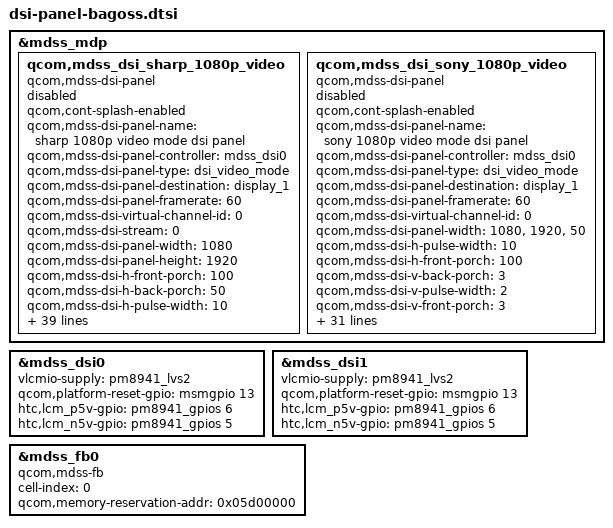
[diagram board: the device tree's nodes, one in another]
&mdss_mdp {
	qcom,mdss_dsi_sharp_1080p_video {
		compatible = "qcom,mdss-dsi-panel";
		status = "disable";
		qcom,cont-splash-enabled;
		qcom,mdss-dsi-panel-name = "sharp 1080p video mode dsi panel";
		qcom,mdss-dsi-panel-controller = <&mdss_dsi0>;
		qcom,mdss-dsi-panel-type = "dsi_video_mode";
		qcom,mdss-dsi-panel-destination = "display_1";
		qcom,mdss-dsi-panel-framerate = <60>;
		qcom,mdss-dsi-virtual-channel-id = <0>;
		qcom,mdss-dsi-stream = <0>;
		qcom,mdss-dsi-panel-width = <1080>;
		qcom,mdss-dsi-panel-height = <1920>;
		qcom,mdss-dsi-h-front-porch = <100>;
		qcom,mdss-dsi-h-back-porch = <50>;
		qcom,mdss-dsi-h-pulse-width = <10>;
		qcom,mdss-dsi-h-sync-skew = <0>;
		qcom,mdss-dsi-v-back-porch = <4>;
		qcom,mdss-dsi-v-front-porch = <4>;
		qcom,mdss-dsi-v-pulse-width = <2>;
		qcom,mdss-dsi-h-left-border = <0>;
		qcom,mdss-dsi-h-right-border = <0>;
		qcom,mdss-dsi-v-top-border = <0>;
		qcom,mdss-dsi-v-bottom-border = <0>;
		qcom,mdss-dsi-bpp = <24>;
		qcom,mdss-dsi-color-order = "rgb_swap_rgb";
		qcom,mdss-dsi-underflow-color = <0xff>;
		qcom,mdss-dsi-border-color = <0>;
		qcom,mdss-dsi-on-command = [29 01 00 00 00 00 02 b0 04 /* interface_setting_0 */
			15 01 00 00 00 00 02 00 00 /* nop */
			15 01 00 00 00 00 02 00 00 /* nop */
			29 01 00 00 00 00 02 d6 01 /* Manufacture_Command_setting */
			29 01 00 00 00 00 02 b3 14 /* Config to Video Mode */
			/* Color_enhancement */
			29 01 00 00 00 00 21 ca 01 02 a4 a4 b8 b4 b0
				a4 3f 28 05 b9 90 70 01
				ff 05 f8 0c 0c 0c 0c 13
				13 f0 20 10 10 10 10 10
				10
			/* BackLight_Control_6 */
			29 01 00 00 00 00 08 ce 00 07 00 c1 24 b2 02
			15 01 00 00 00 00 02 53 24 /* write_control_display */
			15 01 00 00 00 00 02 55 01 /* CABC */
			15 01 00 00 00 00 02 35 00 /* TE_OUT */
			05 01 00 00 78 00 02 11 00 ];
		qcom,mdss-dsi-off-command = [29 01 00 00 14 00 02 28 00 /* display_off */
			29 01 00 00 32 00 02 10 00];
		qcom,mdss-dsi-on-command-state = "dsi_lp_mode"
		qcom,mdss-dsi-off-command-state = "dsi_hs_mode"

		qcom,mdss-dsi-h-sync-pulse = <0>;
		qcom,mdss-dsi-traffic-mode = "non_burst_sync_event";
		qcom,mdss-dsi-bllp-power-mode;
		qcom,mdss-dsi-bllp-eof-power-mode
		qcom,mdss-dsi-lane-map = "lane_map_0123";
		qcom,mdss-dsi-lane-0-state;
		qcom,mdss-dsi-lane-1-state;
		qcom,mdss-dsi-lane-2-state;
		qcom,mdss-dsi-lane-3-state;
		qcom,mdss-dsi-panel-timings = [c8 40 33 00 57 51 35 42 55 03 04 00];
		qcom,mdss-dsi-t-clk-post = <0x02>;
		qcom,mdss-dsi-t-clk-pre = <0x2a>;
		qcom,mdss-dsi-bl-min-level = <1>;
		qcom,mdss-dsi-bl-max-level = <4095>;
		qcom,mdss-dsi-dma-trigger = "trigger_sw";
		qcom,mdss-dsi-mdp-trigger = "none";
		qcom,mdss-dsi-bl-pmic-control-type = "bl_ctrl_wled";

		qcom,display-on-cmds = [39 01 00 00 00 00 02 29 00];
		qcom,mdss-pan-physical-width-dimension = <61>;
		qcom,mdss-pan-physical-height-dimension = <109>;
	};

	qcom,mdss_dsi_sony_1080p_video {
        compatible = "qcom,mdss-dsi-panel";
		status = "disable";
		qcom,cont-splash-enabled;
		qcom,mdss-dsi-panel-name = "sony 1080p video mode dsi panel";
		qcom,mdss-dsi-panel-controller = <&mdss_dsi0>;

		qcom,mdss-dsi-panel-type = "dsi_video_mode";
		qcom,mdss-dsi-panel-destination = "display_1";
		qcom,mdss-dsi-panel-framerate = <60>;
		qcom,mdss-dsi-virtual-channel-id = <0>;
		qcom,mdss-dsi-panel-width = <1080>
		qcom,mdss-dsi-panel-height = <1920>
		qcom,mdss-dsi-h-back-porch = <50>;
		qcom,mdss-dsi-h-pulse-width = <10>;
		qcom,mdss-dsi-h-front-porch = <100>;
		qcom,mdss-dsi-v-back-porch = <3>;
		qcom,mdss-dsi-v-pulse-width = <2>;
		qcom,mdss-dsi-v-front-porch = <3>;
		qcom,mdss-dsi-underflow-color = <0xff>;
		qcom,mdss-dsi-h-sync-pulse = <0>
		qcom,mdss-dsi-bllp-power-mode;
		qcom,mdss-dsi-bllp-eof-power-mode
		qcom,mdss-dsi-bpp = <24>;
		qcom,mdss-dsi-traffic-mode = "non_burst_sync_event";
		qcom,mdss-dsi-color-order = "rgb_swap_rgb";
		qcom,mdss-dsi-on-command = [29 01 00 00 00 00 02 b0 04	/* interface_setting_0 */
			15 01 00 00 00 00 02 00 00 /* nop */
			15 01 00 00 00 00 02 00 00 /* nop */
			/* hsync output */
			29 01 00 00 00 00 04 c3 01 00 10
			/* Color_enhancement */
			29 01 00 00 0a 00 21 ca 01 02 a4 a4 b8 b4 b0
				a4 3f 28 05 b9 90 70 01
				ff 05 f8 0c 0c 0c 0c 13
				13 f0 20 10 10 10 10 10
				10
			/* BackLight_Control_6 */
			29 01 00 00 00 00 08 ce 00 07 00 c1 24 b2 02
			29 01 00 00 00 00 02 d6 01 /* Manufacture Command setting */
			29 01 00 00 00 00 02 b0 03 /* protect on */
			15 01 00 00 00 00 02 00 00 /* nop */
			15 01 00 00 00 00 02 00 00 /* nop */
			15 01 00 00 00 00 02 55 01 /* CABC */
			15 01 00 00 00 00 02 53 24 /* write_control_display */
			15 01 00 00 00 00 02 35 00 /* TE_OUT */
			05 01 00 00 78 00 02 11 00 ];
		qcom,mdss-dsi-off-command = [29 01 00 00 14 00 02 28 00 /* display_off */
		                       29 01 00 00 32 00 02 10 00 /* enter sleep 1 */
		                       29 01 00 00 00 00 02 b0 04 /* interface setting 0 */
		                       15 01 00 00 00 00 02 00 00 /* nop */
		                       15 01 00 00 00 00 02 00 00 /* nop */
		                       29 01 00 00 00 00 02 b0 01 /* interface setting 0 */];
		qcom,mdss-dsi-on-command-state = "dsi_lp_mode"
		qcom,mdss-dsi-off-command-state = "dsi_hs_mode"
		qcom,mdss-dsi-lane-0-state;
		qcom,mdss-dsi-lane-1-state;
		qcom,mdss-dsi-lane-2-state;
		qcom,mdss-dsi-lane-3-state;
		qcom,mdss-dsi-lane-map = "lane_map_0123";
		qcom,mdss-dsi-t-clk-post = <0x02>;
		qcom,mdss-dsi-t-clk-pre = <0x2a>;
		qcom,mdss-dsi-stream = <0>;
		qcom,mdss-dsi-mdp-trigger = "none";
		qcom,mdss-dsi-dma-trigger = "trigger_sw";
		qcom,mdss-dsi-panel-timings = [cb 40 33 00 57 51 35 42 52 03 04 00];

		qcom,mdss-dsi-bl-min-level = <1>;
		qcom,mdss-dsi-bl-max-level = <4095>;
		qcom,mdss-dsi-bl-pmic-control-type = "bl_ctrl_wled";

		qcom,display-on-cmds = [39 01 00 00 00 00 02 29 00];
		qcom,mdss-pan-physical-width-dimension = <61>;
		qcom,mdss-pan-physical-height-dimension = <109>;
	};
};

&mdss_dsi0 {
	vlcmio-supply = <&pm8941_lvs2>;      /* lcm 1v8 */
	qcom,platform-reset-gpio = <&msmgpio 13 0>;
	htc,lcm_p5v-gpio = <&pm8941_gpios 6 0>;
	htc,lcm_n5v-gpio = <&pm8941_gpios 5 0>;
};

&mdss_dsi1 {
	vlcmio-supply = <&pm8941_lvs2>;      /* lcm 1v8 */
	qcom,platform-reset-gpio = <&msmgpio 13 0>;
	htc,lcm_p5v-gpio = <&pm8941_gpios 6 0>;
	htc,lcm_n5v-gpio = <&pm8941_gpios 5 0>;
};

&mdss_fb0 {
	cell-index = <0>;
	compatible = "qcom,mdss-fb";
	/* qcom,memory-reservation-type = "EBI1";
	qcom,memory-reservation-size = <0x1800000>; */  /* FB size for dynamic allocation */
	qcom,memory-reservation-addr = <0x05d00000>;
};
